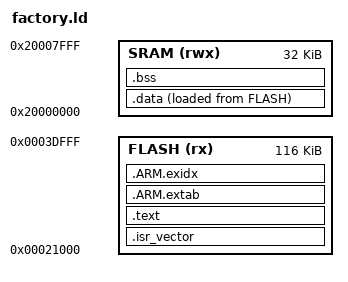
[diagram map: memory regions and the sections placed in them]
/* 厂测镜像 @ APP_B 0x00021000, 116 KB（仅生成 bin，不直接运行） */
MEMORY
{
    FLASH (rx)  : ORIGIN = 0x00021000, LENGTH = 116K
    SRAM  (rwx) : ORIGIN = 0x20000000, LENGTH = 32K
}

_estack = ORIGIN(SRAM) + LENGTH(SRAM);

SECTIONS
{
    .isr_vector :
    {
        KEEP(*(.isr_vector))
    } > FLASH

    .text :
    {
        *(.text*)
        *(.rodata*)
        KEEP(*(.init))
        KEEP(*(.fini))
        . = ALIGN(4);
    } > FLASH

    .ARM.extab :
    {
        *(.ARM.extab* .gnu.linkonce.armextab.*)
    } > FLASH

    .ARM.exidx :
    {
        *(.ARM.exidx* .gnu.linkonce.armexidx.*)
    } > FLASH

    _sidata = LOADADDR(.data);

    .data :
    {
        . = ALIGN(4);
        _sdata = .;
        *(.data*)
        . = ALIGN(4);
        _edata = .;
    } > SRAM AT > FLASH

    .bss :
    {
        . = ALIGN(4);
        _sbss = .;
        *(.bss*)
        *(COMMON)
        . = ALIGN(4);
        _ebss = .;
    } > SRAM

    . = ALIGN(4);
    end = .;
}
